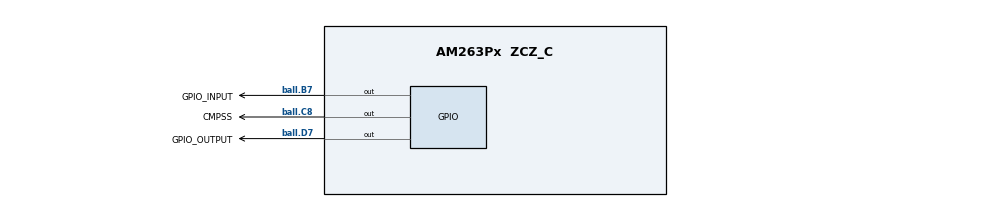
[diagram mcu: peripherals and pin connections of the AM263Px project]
/**
 * @cliArgs --device "AM263Px" --package "ZCZ_C" --part "AM263P1" --context "r5fss0-0" --product "MCU_PLUS_SDK@07.03.01"
 * @versions {"tool":"1.15.0+2826"}
 */

/**
 * Import the modules used in this configuration.
 */
const cmpss      = scripting.addModule("/drivers/cmpss/cmpss", {}, false);
const cmpss1     = cmpss.addInstance();
const gpio       = scripting.addModule("/drivers/gpio/gpio", {}, false);
const gpio1      = gpio.addInstance();
const gpio2      = gpio.addInstance();
const gpio3      = gpio.addInstance();
const uart       = scripting.addModule("/drivers/uart/uart", {}, false);
const uart1      = uart.addInstance();
const clock      = scripting.addModule("/kernel/dpl/clock");
const debug_log  = scripting.addModule("/kernel/dpl/debug_log");
const mpu_armv7  = scripting.addModule("/kernel/dpl/mpu_armv7", {}, false);
const mpu_armv71 = mpu_armv7.addInstance();
const mpu_armv72 = mpu_armv7.addInstance();
const mpu_armv73 = mpu_armv7.addInstance();
const mpu_armv74 = mpu_armv7.addInstance();

/**
 * Write custom configuration values to the imported modules.
 */
cmpss1.$name = "CONFIG_CMPSS0";

gpio1.$name                = "GPIO_INPUT";
gpio1.GPIO.gpioPin.$assign = "ball.B7";

gpio2.pinDir               = "OUTPUT";
gpio2.$name                = "GPIO_OUTPUT";
gpio2.GPIO.gpioPin.$assign = "ball.D7";

gpio3.$name                = "CMPSS";
gpio3.GPIO.gpioPin.$assign = "ball.C8";

uart1.$name            = "TESTER_UART";
uart1.UART.$assign     = "UART3";
uart1.UART.RXD.$assign = "ball.C11";
uart1.UART.TXD.$assign = "ball.A11";

debug_log.enableUartLog            = true;
debug_log.enableCssLog             = false;
debug_log.uartLog.$name            = "CONFIG_UART0";
debug_log.uartLog.UART.RXD.$assign = "ball.A7";
debug_log.uartLog.UART.TXD.$assign = "ball.A6";

mpu_armv71.$name             = "CONFIG_MPU_REGION0";
mpu_armv71.size              = 31;
mpu_armv71.attributes        = "Device";
mpu_armv71.accessPermissions = "Supervisor RD+WR, User RD";
mpu_armv71.allowExecute      = false;

mpu_armv72.$name             = "CONFIG_MPU_REGION1";
mpu_armv72.size              = 15;
mpu_armv72.accessPermissions = "Supervisor RD+WR, User RD";

mpu_armv73.$name             = "CONFIG_MPU_REGION2";
mpu_armv73.baseAddr          = 0x80000;
mpu_armv73.size              = 15;
mpu_armv73.accessPermissions = "Supervisor RD+WR, User RD";

mpu_armv74.$name             = "CONFIG_MPU_REGION3";
mpu_armv74.accessPermissions = "Supervisor RD+WR, User RD";
mpu_armv74.baseAddr          = 0x70000000;
mpu_armv74.size              = 21;

/**
 * Pinmux solution for unlocked pins/peripherals. This ensures that minor changes to the automatic solver in a future
 * version of the tool will not impact the pinmux you originally saw.  These lines can be completely deleted in order to
 * re-solve from scratch.
 */
gpio1.GPIO.$suggestSolution             = "GPIO";
gpio2.GPIO.$suggestSolution             = "GPIO";
gpio3.GPIO.$suggestSolution             = "GPIO";
debug_log.uartLog.UART.$suggestSolution = "UART0";
